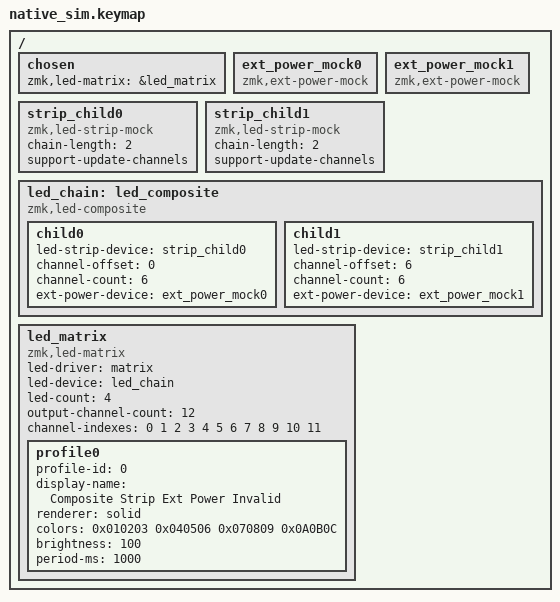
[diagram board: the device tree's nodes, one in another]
#include "../behavior_keymap.dtsi"

/ {
    chosen {
        zmk,led-matrix = &led_matrix;
    };

    ext_power_mock0: ext_power_mock0 {
        compatible = "zmk,ext-power-mock";
    };

    ext_power_mock1: ext_power_mock1 {
        compatible = "zmk,ext-power-mock";
    };

    strip_child0: strip_child0 {
        compatible = "zmk,led-strip-mock";
        chain-length = <2>;
        support-update-channels;
    };

    strip_child1: strip_child1 {
        compatible = "zmk,led-strip-mock";
        chain-length = <2>;
        support-update-channels;
    };

    led_chain: led_composite {
        compatible = "zmk,led-composite";

        child0 {
            led-strip-device = <&strip_child0>;
            channel-offset = <0>;
            channel-count = <6>;
            ext-power-device = <&ext_power_mock0>;
        };

        child1 {
            led-strip-device = <&strip_child1>;
            channel-offset = <6>;
            channel-count = <6>;
            ext-power-device = <&ext_power_mock1>;
        };
    };

    led_matrix: led_matrix {
        compatible = "zmk,led-matrix";
        led-driver = "matrix";
        led-device = <&led_chain>;
        led-count = <4>;
        output-channel-count = <12>;
        channel-indexes = <
            0 1 2
            3 4 5
            6 7 8
            9 10 11
        >;

        profile0 {
            profile-id = <0>;
            display-name = "Composite Strip Ext Power Invalid";
            renderer = "solid";
            colors = <0x010203 0x040506 0x070809 0x0A0B0C>;
            brightness = <100>;
            period-ms = <1000>;
        };
    };
};
